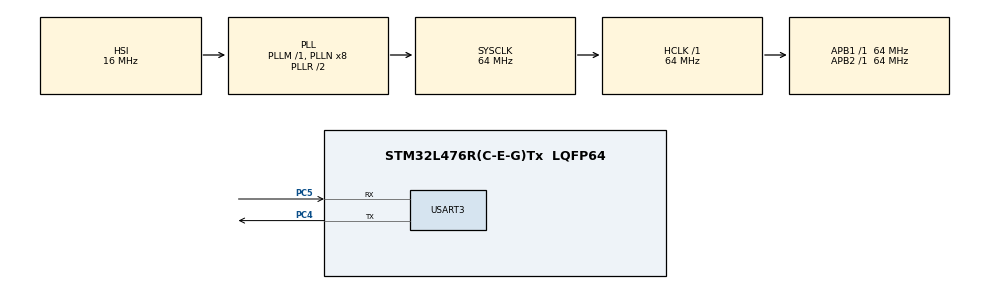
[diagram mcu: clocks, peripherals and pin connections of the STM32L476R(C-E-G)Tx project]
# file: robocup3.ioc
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FREERTOS.INCLUDE_vTaskDelayUntil=1
FREERTOS.Tasks01=MwPeriodicTask,0,128,StartMwPeriodicTask,Default,NULL,Dynamic,NULL,NULL;LowLevelPeriodi,3,128,StartLowLevelPeriodicTask,Default,NULL,Dynamic,NULL,NULL;AppPeriodicTask,1,128,StartAppPeriodicTask,Default,NULL,Dynamic,NULL,NULL
Mcu.Family=STM32L4
Mcu.Name=STM32L476R(C-E-G)Tx
Mcu.Package=LQFP64
NVIC.PriorityGroup=NVIC_PRIORITYGROUP_4
NVIC.TIM7_IRQn=true\:0\:0\:false\:false\:true\:false\:false\:true
NVIC.TimeBase=TIM7_IRQn
NVIC.TimeBaseIP=TIM7
NVIC.USART3_IRQn=true\:5\:0\:false\:false\:true\:true\:true\:true
PA13\ (JTMS-SWDIO).Mode=Serial_Wire
PA13\ (JTMS-SWDIO).Signal=SYS_JTMS-SWDIO
PA14\ (JTCK-SWCLK).Mode=Serial_Wire
PA14\ (JTCK-SWCLK).Signal=SYS_JTCK-SWCLK
PC4.Mode=Asynchronous
PC4.Signal=USART3_TX
PC5.Mode=Asynchronous
PC5.Signal=USART3_RX
ProjectManager.HeapSize=0x200
ProjectManager.StackSize=0x400
ProjectManager.TargetToolchain=STM32CubeIDE
RCC.ADCFreq_Value=64000000
RCC.AHBFreq_Value=64000000
RCC.APB1Freq_Value=64000000
RCC.APB1TimFreq_Value=64000000
RCC.APB2Freq_Value=64000000
RCC.APB2TimFreq_Value=64000000
RCC.CortexFreq_Value=64000000
RCC.DATA_CACHE_ENABLE=0
RCC.HCLKFreq_Value=64000000
RCC.HSE_VALUE=8000000
RCC.HSI_VALUE=16000000
RCC.LSE_VALUE=32768
RCC.MSI_VALUE=4000000
RCC.PLLSourceVirtual=RCC_PLLSOURCE_HSI
RCC.SYSCLKFreq_VALUE=64000000
RCC.SYSCLKSource=RCC_SYSCLKSOURCE_PLLCLK
RCC.USBFreq_Value=64000000
RCC.VCOOutputFreq_Value=128000000
USART3.VirtualMode-Asynchronous=VM_ASYNC
VP_FREERTOS_VS_CMSIS_V1.Mode=CMSIS_V1
VP_SYS_VS_tim7.Mode=TIM7
board=NUCLEO-L476RG

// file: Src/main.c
/* USER CODE BEGIN Header */
/**
  ******************************************************************************
  * @file           : main.c
  * @brief          : Main program body
  ******************************************************************************
  * @attention
  *
  * <h2><center>&copy; Copyright (c) 2020 STMicroelectronics.
  * All rights reserved.</center></h2>
  *
  * This software component is licensed by ST under BSD 3-Clause license,
  * the "License"; You may not use this file except in compliance with the
  * License. You may obtain a copy of the License at:
  *                        opensource.org/licenses/BSD-3-Clause
  *
  ******************************************************************************
  */
/* USER CODE END Header */

#include "main.h"
#include "cmsis_os.h"

/* USER CODE BEGIN Includes */
#include "Initialize_System.h"
#include "UART.h"
#include "fifo.h"
#include "Common_Data.h"
#include "CommunicationRxWrapper.h"
#include "CommunicationTxWrapper.h"
/* USER CODE END Includes */

UART_HandleTypeDef huart3;

osThreadId MwPeriodicTaskHandle;
osThreadId LowLevelPeriodiHandle;
osThreadId AppPeriodicTaskHandle;
/* USER CODE BEGIN PV */
uint32_t sys_count=0;
uint32_t get_sys_count=0;
uint8_t UartReady = 0;
uint8_t Startup_tx_message[3]={0xAA, 0x15, 0xCC};

extern uint8_t aRxBuffer[RXBUFFERSIZE];
/* USER CODE END PV */

void SystemClock_Config(void);
static void MX_GPIO_Init(void);
static void MX_USART3_UART_Init(void);
void StartMwPeriodicTask(void const * argument);
void StartLowLevelPeriodicTask(void const * argument);
void StartAppPeriodicTask(void const * argument);

int main(void)
{

  /* MCU Configuration--------------------------------------------------------*/

  /* Reset of all peripherals, Initializes the Flash interface and the Systick. */
  HAL_Init();

  /* Configure the system clock */
  SystemClock_Config();

  /* Initialize all configured peripherals */

  /* USER CODE BEGIN 2 */
  Init_System_Startup();

  HAL_Delay(30000);
  MX_GPIO_Init();
  MX_USART3_UART_Init();

  HAL_UART_Receive_IT(&huart3, (uint8_t *)aRxBuffer, RXBUFFERSIZE);
  HAL_UART_Transmit_IT(&huart3, (uint8_t *)Startup_tx_message, 3);

  /* USER CODE END 2 */

  /* Create the thread(s) */
  /* definition and creation of MwPeriodicTask */
  osThreadDef(MwPeriodicTask, StartMwPeriodicTask, osPriorityNormal, 0, 128);
  MwPeriodicTaskHandle = osThreadCreate(osThread(MwPeriodicTask), NULL);

  /* definition and creation of LowLevelPeriodi */
  osThreadDef(LowLevelPeriodi, StartLowLevelPeriodicTask, osPriorityRealtime, 0, 128);
  LowLevelPeriodiHandle = osThreadCreate(osThread(LowLevelPeriodi), NULL);

  /* definition and creation of AppPeriodicTask */
  osThreadDef(AppPeriodicTask, StartAppPeriodicTask, osPriorityAboveNormal, 0, 128);
  AppPeriodicTaskHandle = osThreadCreate(osThread(AppPeriodicTask), NULL);

  /* Start scheduler */
  osKernelStart();

  /* We should never get here as control is now taken by the scheduler */

  /* Infinite loop */
  while (1)
  {

  }
}

void SystemClock_Config(void)
{
  RCC_OscInitTypeDef RCC_OscInitStruct = {0};
  RCC_ClkInitTypeDef RCC_ClkInitStruct = {0};
  RCC_PeriphCLKInitTypeDef PeriphClkInit = {0};

  /** Initializes the CPU, AHB and APB busses clocks
  */
  RCC_OscInitStruct.OscillatorType = RCC_OSCILLATORTYPE_HSI;
  RCC_OscInitStruct.HSIState = RCC_HSI_ON;
  RCC_OscInitStruct.HSICalibrationValue = RCC_HSICALIBRATION_DEFAULT;
  RCC_OscInitStruct.PLL.PLLState = RCC_PLL_ON;
  RCC_OscInitStruct.PLL.PLLSource = RCC_PLLSOURCE_HSI;
  RCC_OscInitStruct.PLL.PLLM = 1;
  RCC_OscInitStruct.PLL.PLLN = 8;
  RCC_OscInitStruct.PLL.PLLP = RCC_PLLP_DIV7;
  RCC_OscInitStruct.PLL.PLLQ = RCC_PLLQ_DIV2;
  RCC_OscInitStruct.PLL.PLLR = RCC_PLLR_DIV2;
  if (HAL_RCC_OscConfig(&RCC_OscInitStruct) != HAL_OK)
  {
    Error_Handler();
  }
  /** Initializes the CPU, AHB and APB busses clocks
  */
  RCC_ClkInitStruct.ClockType = RCC_CLOCKTYPE_HCLK|RCC_CLOCKTYPE_SYSCLK
                              |RCC_CLOCKTYPE_PCLK1|RCC_CLOCKTYPE_PCLK2;
  RCC_ClkInitStruct.SYSCLKSource = RCC_SYSCLKSOURCE_PLLCLK;
  RCC_ClkInitStruct.AHBCLKDivider = RCC_SYSCLK_DIV1;
  RCC_ClkInitStruct.APB1CLKDivider = RCC_HCLK_DIV1;
  RCC_ClkInitStruct.APB2CLKDivider = RCC_HCLK_DIV1;

  if (HAL_RCC_ClockConfig(&RCC_ClkInitStruct, FLASH_LATENCY_3) != HAL_OK)
  {
    Error_Handler();
  }
  PeriphClkInit.PeriphClockSelection = RCC_PERIPHCLK_USART3;
  PeriphClkInit.Usart3ClockSelection = RCC_USART3CLKSOURCE_PCLK1;
  if (HAL_RCCEx_PeriphCLKConfig(&PeriphClkInit) != HAL_OK)
  {
    Error_Handler();
  }
  /** Configure the main internal regulator output voltage
  */
  if (HAL_PWREx_ControlVoltageScaling(PWR_REGULATOR_VOLTAGE_SCALE1) != HAL_OK)
  {
    Error_Handler();
  }
}

static void MX_USART3_UART_Init(void)
{

  huart3.Instance = USART3;
  huart3.Init.BaudRate = 115200;
  huart3.Init.WordLength = UART_WORDLENGTH_8B;
  huart3.Init.StopBits = UART_STOPBITS_1;
  huart3.Init.Parity = UART_PARITY_NONE;
  huart3.Init.Mode = UART_MODE_TX_RX;
  huart3.Init.HwFlowCtl = UART_HWCONTROL_NONE;
  huart3.Init.OverSampling = UART_OVERSAMPLING_16;
  huart3.Init.OneBitSampling = UART_ONE_BIT_SAMPLE_DISABLE;
  huart3.AdvancedInit.AdvFeatureInit = UART_ADVFEATURE_NO_INIT;
  if (HAL_UART_Init(&huart3) != HAL_OK)
  {
    Error_Handler();
  }

}

static void MX_GPIO_Init(void)
{

  /* GPIO Ports Clock Enable */
  __HAL_RCC_GPIOC_CLK_ENABLE();
  __HAL_RCC_GPIOA_CLK_ENABLE();

}

void StartMwPeriodicTask(void const * argument)
{

  /* USER CODE BEGIN 5 */
	//TickType_t xLastWakeTime;
	//uint32_t last_data;
	//const TickType_t xFrequency = 0.250 / portTICK_PERIOD_MS;

	// Initialise the xLastWakeTime variable with the current time.
	//xLastWakeTime = xTaskGetTickCount();
  /* Infinite loop */
  for(;;)
  {
	//vTaskDelayUntil( &xLastWakeTime, xFrequency );
	CommunicationRxWrapper();
	CommunicationTxWrapper();

  }
  /* USER CODE END 5 */
}

void StartLowLevelPeriodicTask(void const * argument)
{
  /* USER CODE BEGIN StartLowLevelPeriodicTask */
	TickType_t xLastWakeTime;
	const TickType_t xFrequency = 10;

	// Initialise the xLastWakeTime variable with the current time.
	xLastWakeTime = xTaskGetTickCount();

  /* Infinite loop */

  for(;;)
  {
	  vTaskDelayUntil( &xLastWakeTime, xFrequency );
  }
  /* USER CODE END StartLowLevelPeriodicTask */
}

void StartAppPeriodicTask(void const * argument)
{
  /* USER CODE BEGIN StartAppPeriodicTask */
	TickType_t xLastWakeTime;
	const TickType_t xFrequency = 2 / portTICK_PERIOD_MS;
	WheelSpeed_Typedef Provided_wheel_speeds;
	Provided_wheel_speeds.WheelSpeed_1=100;
	Write_Calculated_Wheel_Speeds(&Provided_wheel_speeds);
	Motorx_Set_Speed();
		// Initialise the xLastWakeTime variable with the current time.
	xLastWakeTime = xTaskGetTickCount();
  /* Infinite loop */
  for(;;)
  {
	  vTaskDelayUntil( &xLastWakeTime, xFrequency );

	  Calculate_Wheel_Speeds();
	  Provide_Wheel_Speeds();
	  PID_Controller();
	  Motorx_Set_Speed();
	  //Actuate_Motors();
  }
  /* USER CODE END StartAppPeriodicTask */
}

void HAL_TIM_PeriodElapsedCallback(TIM_HandleTypeDef *htim)
{
  if (htim->Instance == TIM7) {
    HAL_IncTick();
  }
}

void Error_Handler(void)
{
  /* USER CODE BEGIN Error_Handler_Debug */
  /* User can add his own implementation to report the HAL error return state */
	while(1);
  /* USER CODE END Error_Handler_Debug */
}

/************************ (C) COPYRIGHT STMicroelectronics *****END OF FILE****/
